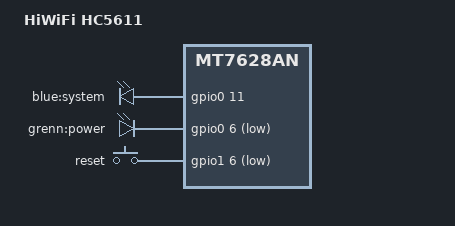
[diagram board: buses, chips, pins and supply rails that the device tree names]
/dts-v1/;

#include "mt7628an_hiwifi_hc5x61a.dtsi"

/ {
	compatible = "hiwifi,hc5611", "mediatek,mt7628an-soc";
	model = "HiWiFi HC5611";

	leds {
		compatible = "gpio-leds";

		led_system:system {
			label = "blue:system";
			gpios = <&gpio0 11 GPIO_ACTIVE_HIGH>;
		};
	
		led_power: power {
			label = "grenn:power";
			gpios = <&gpio0 6 GPIO_ACTIVE_LOW>;
			linux,code = <KEY_RESTART>;

		};
	};
	keys {
		compatible = "gpio-keys-polled";
		poll-interval = <20>;

		reset {
			label = "reset";
			gpios = <&gpio1 6 GPIO_ACTIVE_LOW>;
			linux,code = <KEY_RESTART>;
		};
	};
};

&state_default {
	gpio {
		groups = "i2c", "refclk", "wled_an";
		function = "gpio";
	};
};

&ehci {
	status = "disabled";
};

&ohci {
	status = "disabled";
};
